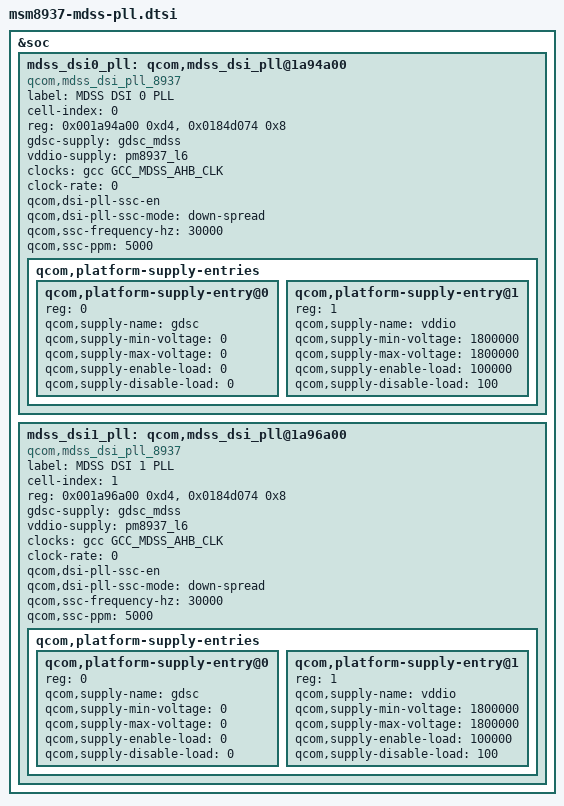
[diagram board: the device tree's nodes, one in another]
/*
 * MSM8937 / MSM8940 的 MDSS DSI PLL。
 *
 * 这两个节点的 compatible 必须是 "qcom,mdss_dsi_pll_8937"：
 * 本仓库为 msm8937 启用了**老时钟框架**（CONFIG_COMMON_CLK_MSM），
 * 对应的 PLL 驱动是 drivers/clk/msm/mdss/mdss-pll.c，它只认
 * qcom,mdss_dsi_pll_8909/8937/8952/8953/sdm439 这几个名字。
 *
 * 之前这里写的是新框架的 "qcom,mdss_dsi_pll_28lpm"，只有
 * drivers/clk/qcom/mdss/mdss-pll.c（COMMON_CLK_QCOM，本仓库没启用）
 * 才支持，于是 PLL 驱动匹配不上、一个时钟都不注册，连锁反应：
 *
 *   clock_gcc_mdss: Failed to get pclk0 source.
 *     -> mdss_mdp_irq_clk_register: unable to get clk: core_clk
 *       -> mdss_mdp_probe: unable to initialize mdss mdp resources
 *         -> 没有显示驱动 -> 黑屏 -> init 按
 *            androidboot.init_fatal_reboot_target=recovery 重启进 recovery
 *
 * clocks 里用的 <&gcc GCC_MDSS_AHB_CLK> 无需改动：msm8952-clk-wrapper.h
 * 已把 gcc 映射到 clock_gcc、GCC_MDSS_AHB_CLK 映射到
 * clk_gcc_mdss_ahb_clk，展开后与 4.9 原版的写法完全等价。
 */

&soc {
	mdss_dsi0_pll: qcom,mdss_dsi_pll@1a94a00 {
		compatible = "qcom,mdss_dsi_pll_8937";
		label = "MDSS DSI 0 PLL";
		cell-index = <0>;
		#clock-cells = <1>;

		reg = <0x001a94a00 0xd4>,
			<0x0184d074 0x8>;
		reg-names = "pll_base", "gdsc_base";

		gdsc-supply = <&gdsc_mdss>;
		vddio-supply = <&pm8937_l6>;

		clocks = <&gcc GCC_MDSS_AHB_CLK>;
		clock-names = "iface_clk";
		clock-rate = <0>;
		qcom,dsi-pll-ssc-en;
		qcom,dsi-pll-ssc-mode = "down-spread";
		qcom,ssc-frequency-hz = <30000>;
		qcom,ssc-ppm = <5000>;

		qcom,platform-supply-entries {
			#address-cells = <1>;
			#size-cells = <0>;

			qcom,platform-supply-entry@0 {
				reg = <0>;
				qcom,supply-name = "gdsc";
				qcom,supply-min-voltage = <0>;
				qcom,supply-max-voltage = <0>;
				qcom,supply-enable-load = <0>;
				qcom,supply-disable-load = <0>;
			};

			qcom,platform-supply-entry@1 {
				reg = <1>;
				qcom,supply-name = "vddio";
				qcom,supply-min-voltage = <1800000>;
				qcom,supply-max-voltage = <1800000>;
				qcom,supply-enable-load = <100000>;
				qcom,supply-disable-load = <100>;
			};
		};
	};

	mdss_dsi1_pll: qcom,mdss_dsi_pll@1a96a00 {
		compatible = "qcom,mdss_dsi_pll_8937";
		label = "MDSS DSI 1 PLL";
		cell-index = <1>;
		#clock-cells = <1>;

		reg = <0x001a96a00 0xd4>,
			<0x0184d074 0x8>;
		reg-names = "pll_base", "gdsc_base";

		gdsc-supply = <&gdsc_mdss>;
		vddio-supply = <&pm8937_l6>;

		clocks = <&gcc GCC_MDSS_AHB_CLK>;
		clock-names = "iface_clk";
		clock-rate = <0>;
		qcom,dsi-pll-ssc-en;
		qcom,dsi-pll-ssc-mode = "down-spread";
		qcom,ssc-frequency-hz = <30000>;
		qcom,ssc-ppm = <5000>;

		qcom,platform-supply-entries {
			#address-cells = <1>;
			#size-cells = <0>;

			qcom,platform-supply-entry@0 {
				reg = <0>;
				qcom,supply-name = "gdsc";
				qcom,supply-min-voltage = <0>;
				qcom,supply-max-voltage = <0>;
				qcom,supply-enable-load = <0>;
				qcom,supply-disable-load = <0>;
			};

			qcom,platform-supply-entry@1 {
				reg = <1>;
				qcom,supply-name = "vddio";
				qcom,supply-min-voltage = <1800000>;
				qcom,supply-max-voltage = <1800000>;
				qcom,supply-enable-load = <100000>;
				qcom,supply-disable-load = <100>;
			};
		};
	};
};
